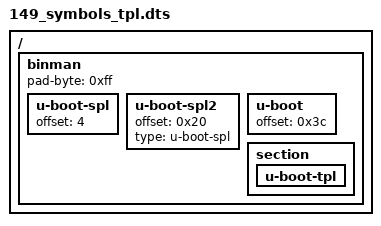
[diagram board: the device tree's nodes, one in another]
/dts-v1/;

/ {
	#address-cells = <1>;
	#size-cells = <1>;

	binman {
		pad-byte = <0xff>;
		u-boot-spl {
			offset = <4>;
		};

		u-boot-spl2 {
			offset = <0x20>;
			type = "u-boot-spl";
		};

		u-boot {
			offset = <0x3c>;
		};

		section {
			u-boot-tpl {
			};
		};
	};
};
